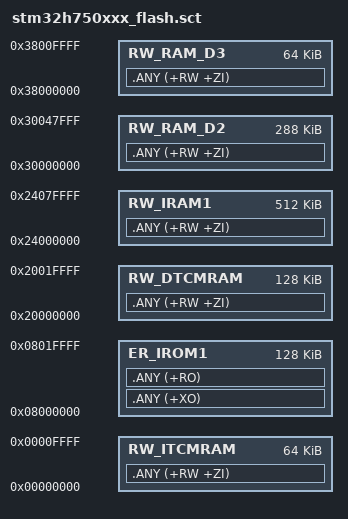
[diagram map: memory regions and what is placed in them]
; *********************************************************************************
; *** Scatter-Loading Description File generated by STM32CubeMX/LinkerGenerator ***
; *********************************************************************************;

LR_IROM1 0x08000000 0x00020000  {  ; load_region size_region
  ER_IROM1 0x08000000 0x00020000  {  ; load address = excetion address
   .ANY (+XO)
   .ANY (+RO)
  }
  RW_IRAM1 0x24000000 0x00080000  {  ; load address = excetion address
   .ANY (+RW +ZI)
  }
  RW_DTCMRAM 0x20000000 0x00020000  {  ; load address = excetion address
   .ANY (+RW +ZI)
  }
  RW_RAM_D2 0x30000000 0x00048000  {  ; load address = excetion address
   .ANY (+RW +ZI)
  }
  RW_RAM_D3 0x38000000 0x00010000  {  ; load address = excetion address
   .ANY (+RW +ZI)
  }
  RW_ITCMRAM 0x00000000 0x00010000  {  ; load address = excetion address
   .ANY (+RW +ZI)
  }
}

